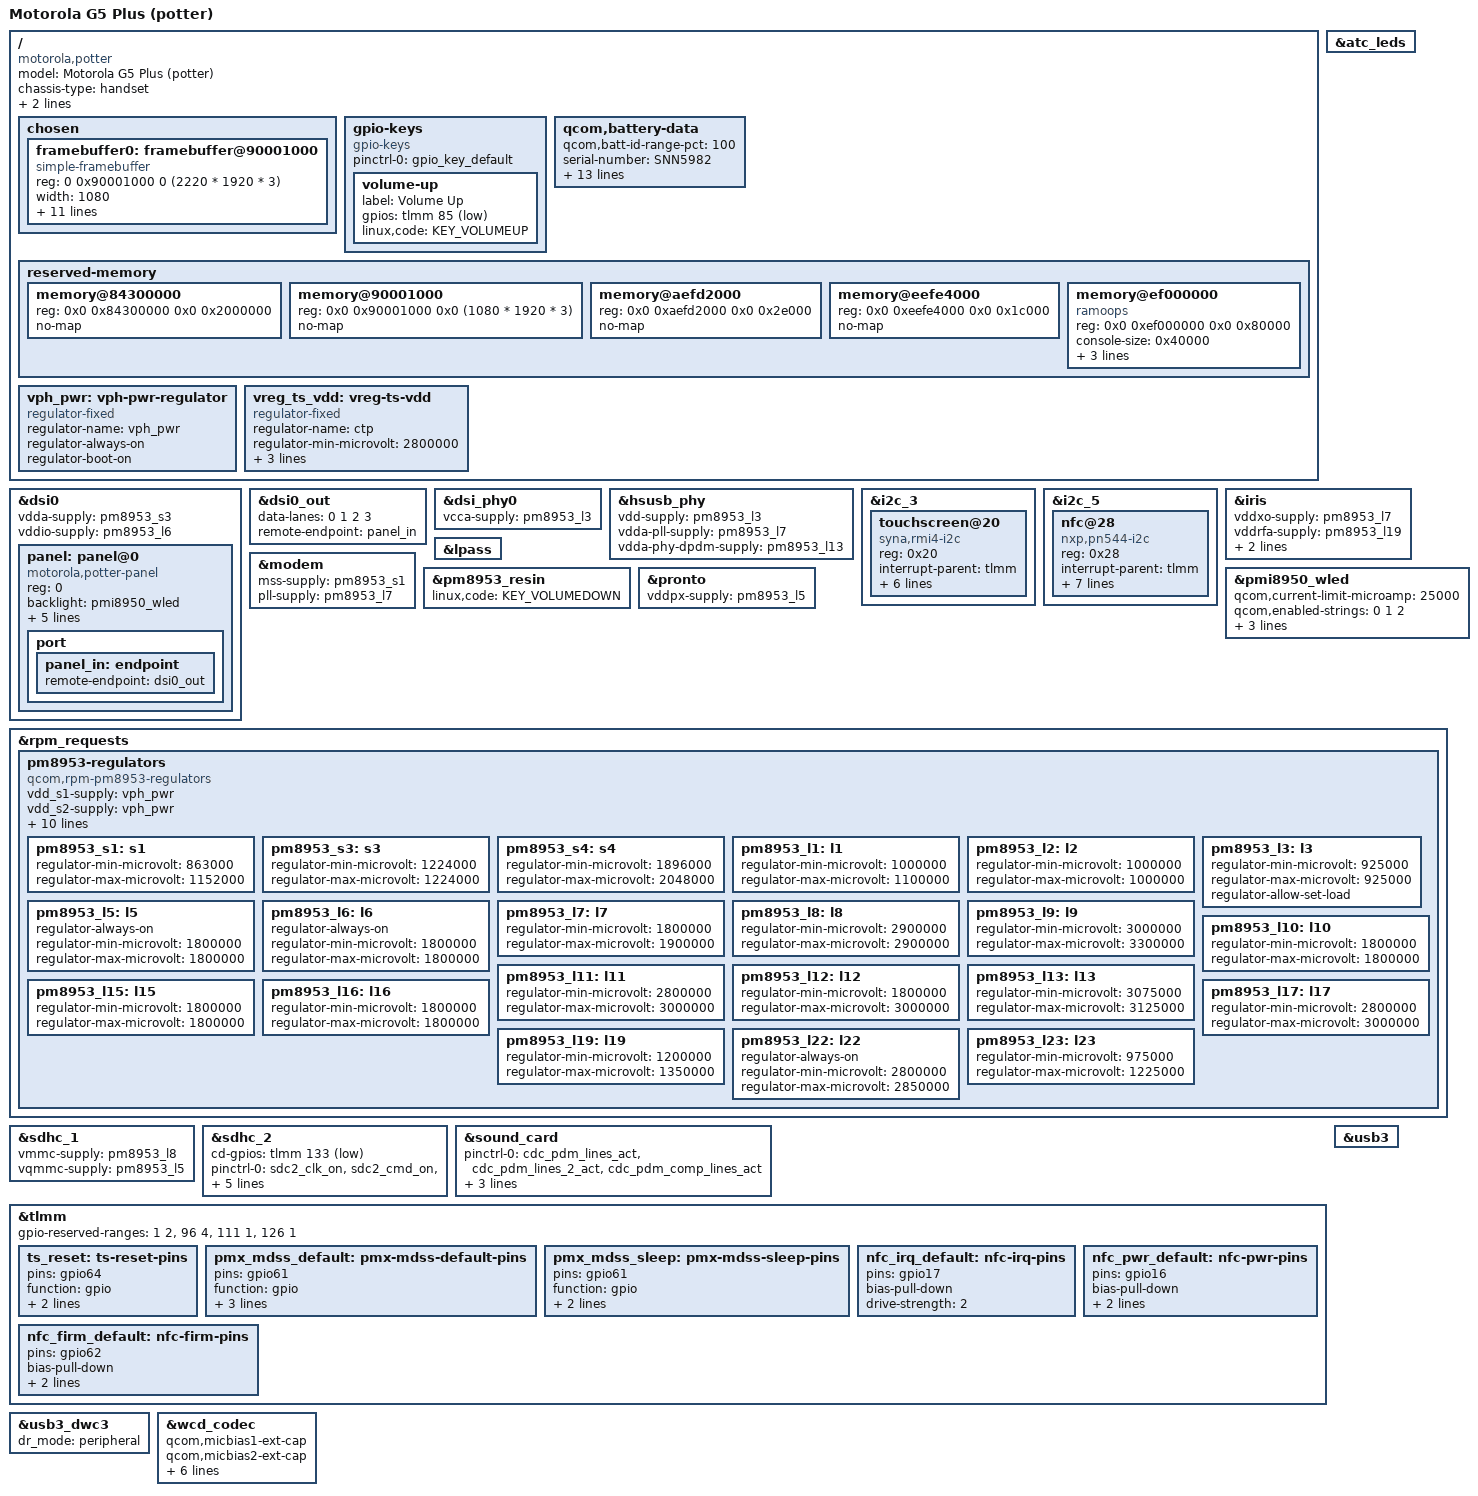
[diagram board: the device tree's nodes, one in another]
/* Copyright (c) 2022 The Linux Foundation. All rights reserved.
 *
 * This program is free software; you can redistribute it and/or modify
 * it under the terms of the GNU General Public License version 2 and
 * only version 2 as published by the Free Software Foundation.
 *
 * This program is distributed in the hope that it will be useful,
 * but WITHOUT ANY WARRANTY; without even the implied warranty of
 * MERCHANTABILITY or FITNESS FOR A PARTICULAR PURPOSE.  See the
 * GNU General Public License for more details.
 */
/dts-v1/;

#include "msm8953.dtsi"
#include "pm8953.dtsi"
#include "pmi8950.dtsi"

/ {
	model = "Motorola G5 Plus (potter)";
	compatible = "motorola,potter", "qcom,msm8953";
	chassis-type = "handset";
	qcom,msm-id = <293 0>;
	qcom,board-id = <0x46 0x83a0>;

	chosen {
		#address-cells = <2>;
		#size-cells = <2>;
		ranges;

		framebuffer0: framebuffer@90001000 {
			compatible = "simple-framebuffer";
			reg = <0 0x90001000 0 (2220 * 1920 * 3)>;

			width = <1080>;
			height = <1920>;
			stride = <(1080 * 3)>;
			format = "r8g8b8";

			power-domains = <&gcc MDSS_GDSC>;

			clocks = <&gcc GCC_MDSS_AHB_CLK>,
				 <&gcc GCC_MDSS_AXI_CLK>,
				 <&gcc GCC_MDSS_VSYNC_CLK>,
				 <&gcc GCC_MDSS_MDP_CLK>,
				 <&gcc GCC_MDSS_BYTE0_CLK>,
				 <&gcc GCC_MDSS_PCLK0_CLK>,
				 <&gcc GCC_MDSS_ESC0_CLK>;
		};
	};

	gpio-keys {
		compatible = "gpio-keys";

		pinctrl-names = "default";
		pinctrl-0 = <&gpio_key_default>;

		volume-up {
			label = "Volume Up";
			gpios = <&tlmm 85 GPIO_ACTIVE_LOW>;
			linux,code = <KEY_VOLUMEUP>;
		};
	};

	qcom,battery-data {
		qcom,batt-id-range-pct = <100>;
		serial-number = "SNN5982";
		manufacturer = "ATL";
		model = "HG40";

		qcom,max-voltage-uv = <4400000>;
		qcom,batt-id-kohm = <0>;
		qcom,battery-beta = <0>;
		qcom,battery-type = "HG40-ATL-3000mah";
		qcom,chg-rslow-comp-c1 = <3073614>;
		qcom,chg-rslow-comp-c2 = <3981400>;
		qcom,chg-rs-to-rslow = <1280731>;
		qcom,chg-rslow-comp-thr = <157>;
		qcom,thermal-coefficients = [69 86 5d 4b 62 35];
		qcom,fg-profile-data = [ E0 83 C3 7C
					 0F 81 36 77
					 65 83 4C 74
					 5C 89 67 94
					 3A 82 6D 99
					 54 BC AA C8
					 56 10 02 88
					 A7 7D A8 81
					 1F 7C 54 83
					 34 6A B6 78
					 21 86 4E 82
					 B5 99 08 BD
					 07 CA 59 0D
					 DE 0B 7F 59
					 14 70 B2 FD
					 E0 35 52 3E
					 FD 16 00 00
					 17 46 56 23
					 5F 28 00 00
					 00 00 00 00
					 00 00 00 00
					 EC 70 41 70
					 31 71 E9 83
					 EF 6E 25 5A
					 34 5A 39 7A
					 A8 6E 4D 5B
					 28 7F 6B 96
					 17 A1 62 44
					 64 A0 71 0C
					 28 00 FF 36
					 F0 11 30 03
					 00 00 00 0C ];
	};

	reserved-memory {
		/delete-node/memory@85b00000;

		memory@84300000 {
			reg = <0x0 0x84300000 0x0 0x2000000>;
			no-map;
		};

		memory@90001000 {
			reg = <0x0 0x90001000 0x0 (1080 * 1920 * 3)>;
			no-map;
		};

		memory@aefd2000 {
			reg = <0x0 0xaefd2000 0x0 0x2e000>;
			no-map;
		};

		memory@eefe4000 {
			reg = <0x0 0xeefe4000 0x0 0x1c000>;
			no-map;
		};

		memory@ef000000 {
			compatible = "ramoops";
			reg = <0x0 0xef000000 0x0 0x80000>;
			console-size = <0x40000>;
			ftrace-size = <0>;
			record-size = <0x3f800>;
			pmsg-size = <0x800>;
		};
	};

	vph_pwr: vph-pwr-regulator {
		compatible = "regulator-fixed";
		regulator-name = "vph_pwr";
		regulator-always-on;
		regulator-boot-on;
	};

	vreg_ts_vdd: vreg-ts-vdd {
		compatible = "regulator-fixed";
		regulator-name = "ctp";

		regulator-min-microvolt = <2800000>;
		regulator-max-microvolt = <2800000>;

		gpio = <&tlmm 64 GPIO_ACTIVE_HIGH>;
		enable-active-high;
	};
};

&atc_leds {
	status = "okay";
};

&dsi0 {
	status = "okay";

	vdda-supply = <&pm8953_s3>;
	vddio-supply = <&pm8953_l6>;

	panel: panel@0 {
		compatible = "motorola,potter-panel";
		reg = <0>;

		backlight = <&pmi8950_wled>;

		pinctrl-names = "default", "sleep";
		pinctrl-0 = <&pmx_mdss_default>;
		pinctrl-1 = <&pmx_mdss_sleep>;

		reset-gpios = <&tlmm 61 GPIO_ACTIVE_LOW>;

		vsp-supply = <&lab_vreg>;
		vsn-supply = <&ibb_vreg>;

		port {
			panel_in: endpoint {
				remote-endpoint = <&dsi0_out>;
			};
		};
	};
};

&dsi0_out {
	data-lanes = <0 1 2 3>;
	remote-endpoint = <&panel_in>;
};

&dsi_phy0 {
	vcca-supply = <&pm8953_l3>;
};

&hsusb_phy {
	status = "okay";

	vdd-supply = <&pm8953_l3>;
	vdda-pll-supply = <&pm8953_l7>;
	vdda-phy-dpdm-supply = <&pm8953_l13>;
};

&i2c_3 {
	status = "okay";

	touchscreen@20 {
		reg = <0x20>;
		compatible = "syna,rmi4-i2c";

		interrupt-parent = <&tlmm>;
		interrupts = <65 IRQ_TYPE_EDGE_FALLING>;

		pinctrl-names = "default";
		pinctrl-0 = <&ts_reset>;

		vdd-supply = <&pm8953_l22>;
		vio-supply = <&pm8953_l6>;

		syna,reset-delay-ms = <200>;
		syna,startup-delay-ms = <500>;
	};
};

&i2c_5 {
	status = "okay";

	nfc@28 {
		compatible = "nxp,pn544-i2c";
		reg = <0x28>;
		interrupt-parent = <&tlmm>;
		interrupts = <17 0x00>; // FIXME

		enable-gpios = <&tlmm 16 GPIO_ACTIVE_HIGH>; /* EN */
		firmware-gpios = <&tlmm 62 GPIO_ACTIVE_HIGH>; /* Firmware */

		nxp,pnxx-discharge-delay = <100>;
		nxp,pnxx-ven-inv-polarity = <0x00>;

		pinctrl-names = "default";
		pinctrl-0 = <&nfc_irq_default &nfc_pwr_default &nfc_firm_default>;
	};
};

&iris {
	vddxo-supply = <&pm8953_l7>;
	vddrfa-supply = <&pm8953_l19>;
	vddpa-supply = <&pm8953_l9>;
	vdddig-supply = <&pm8953_l5>;
};

&lpass {
	status = "okay";
};

&modem {
	status = "okay";

	mss-supply = <&pm8953_s1>;
	pll-supply = <&pm8953_l7>;
};

&pm8953_resin {
	status = "okay";
	linux,code = <KEY_VOLUMEDOWN>;
};

&pmi8950_wled {
	status = "okay";

	/* Don't copy-paste! See pmi8950.dtsi */

	qcom,current-limit-microamp = <25000>;
	qcom,enabled-strings = <0 1 2>;
	qcom,num-strings = <3>;

	qcom,cabc;
	qcom,eternal-pfet;
};

&pronto {
	status = "okay";

	vddpx-supply = <&pm8953_l5>;
};

&rpm_requests {
	pm8953-regulators {
		compatible = "qcom,rpm-pm8953-regulators";
		vdd_s1-supply = <&vph_pwr>;
		vdd_s2-supply = <&vph_pwr>;
		vdd_s3-supply = <&vph_pwr>;
		vdd_s4-supply = <&vph_pwr>;
		vdd_s5-supply = <&vph_pwr>;
		vdd_s6-supply = <&vph_pwr>;
		vdd_s7-supply = <&vph_pwr>;
		vdd_l1-supply = <&pm8953_s3>;
		vdd_l2_l3-supply = <&pm8953_s3>;
		vdd_l4_l5_l6_l7_l16_l19-supply = <&pm8953_s4>;
		vdd_l8_l11_l12_l13_l14_l15-supply = <&vph_pwr>;
		vdd_l9_l10_l17_l18_l22-supply = <&vph_pwr>;

		pm8953_s1: s1 {
			regulator-min-microvolt = <863000>;
			regulator-max-microvolt = <1152000>;
		};

		pm8953_s3: s3 {
			regulator-min-microvolt = <1224000>;
			regulator-max-microvolt = <1224000>;
		};

		pm8953_s4: s4 {
			regulator-min-microvolt = <1896000>;
			regulator-max-microvolt = <2048000>;
		};

		pm8953_l1: l1 {
			regulator-min-microvolt = <1000000>;
			regulator-max-microvolt = <1100000>;
		};

		pm8953_l2: l2 {
			regulator-min-microvolt = <1000000>;
			regulator-max-microvolt = <1000000>;
		};

		pm8953_l3: l3 {
			regulator-min-microvolt = <925000>;
			regulator-max-microvolt = <925000>;
			regulator-allow-set-load;
		};

		pm8953_l5: l5 {
			/* May fix sdcard detection */
			regulator-always-on;
			regulator-min-microvolt = <1800000>;
			regulator-max-microvolt = <1800000>;
		};

		pm8953_l6: l6 {
			regulator-always-on;
			regulator-min-microvolt = <1800000>;
			regulator-max-microvolt = <1800000>;
		};

		pm8953_l7: l7 {
			regulator-min-microvolt = <1800000>;
			regulator-max-microvolt = <1900000>;
		};

		pm8953_l8: l8 {
			regulator-min-microvolt = <2900000>;
			regulator-max-microvolt = <2900000>;
		};

		pm8953_l9: l9 {
			regulator-min-microvolt = <3000000>;
			regulator-max-microvolt = <3300000>;
		};

		pm8953_l10: l10 {
			regulator-min-microvolt = <1800000>;
			regulator-max-microvolt = <1800000>;
		};

		pm8953_l11: l11 {
			regulator-min-microvolt = <2800000>;
			regulator-max-microvolt = <3000000>;
		};

		pm8953_l12: l12 {
			regulator-min-microvolt = <1800000>;
			regulator-max-microvolt = <3000000>;
		};

		pm8953_l13: l13 {
			regulator-min-microvolt = <3075000>;
			regulator-max-microvolt = <3125000>;
		};

		pm8953_l15: l15 {
			regulator-min-microvolt = <1800000>;
			regulator-max-microvolt = <1800000>;
		};

		pm8953_l16: l16 {
			regulator-min-microvolt = <1800000>;
			regulator-max-microvolt = <1800000>;
		};

		pm8953_l17: l17 {
			regulator-min-microvolt = <2800000>;
			regulator-max-microvolt = <3000000>;
		};

		pm8953_l19: l19 {
			regulator-min-microvolt = <1200000>;
			regulator-max-microvolt = <1350000>;
		};

		pm8953_l22: l22 {
			regulator-always-on;
			regulator-min-microvolt = <2800000>;
			regulator-max-microvolt = <2850000>;
		};

		pm8953_l23: l23 {
			regulator-min-microvolt = <975000>;
			regulator-max-microvolt = <1225000>;
		};
	};
};

&sdhc_1 {
	status = "okay";

	vmmc-supply = <&pm8953_l8>;
	vqmmc-supply = <&pm8953_l5>;
};

&sdhc_2 {
	status = "okay";

	cd-gpios = <&tlmm 133 GPIO_ACTIVE_LOW>;

	pinctrl-names = "default", "sleep";
	pinctrl-0 = <&sdc2_clk_on &sdc2_cmd_on &sdc2_data_on &sdc2_cd_off>;
	pinctrl-1 = <&sdc2_clk_off &sdc2_cmd_off &sdc2_data_off &sdc2_cd_off>;

	vmmc-supply = <&pm8953_l11>;
	vqmmc-supply = <&pm8953_l12>;
};

&sound_card {
	status = "okay";

	pinctrl-names = "default", "sleep";
	pinctrl-0 = <&cdc_pdm_lines_act &cdc_pdm_lines_2_act &cdc_pdm_comp_lines_act>;
	pinctrl-1 = <&cdc_pdm_lines_sus &cdc_pdm_lines_2_sus &cdc_pdm_comp_lines_act>;

	model = "msm8916";
};

&tlmm {
	gpio-reserved-ranges = <1 2>, <96 4>, <111 1>, <126 1>;

	ts_reset: ts-reset-pins {
		pins = "gpio64";
		function = "gpio";
		drive-strength = <2>;
		bias-pull-up;
	};

	pmx_mdss_default: pmx-mdss-default-pins {
		pins = "gpio61";
		function = "gpio";
		drive-strength = <8>;
		bias-disable;
		output-high;
	};

	pmx_mdss_sleep: pmx-mdss-sleep-pins {
		pins = "gpio61";
		function = "gpio";
		drive-strength = <2>;
		bias-pull-down;
	};


	nfc_irq_default: nfc-irq-pins {
		pins = "gpio17";
		bias-pull-down;
		drive-strength = <2>;
	};

	nfc_pwr_default: nfc-pwr-pins {
		pins = "gpio16";
		bias-pull-down;
		output-low;
		drive-strength = <2>;
	};

	nfc_firm_default: nfc-firm-pins {
		pins = "gpio62";
		bias-pull-down;
		output-low;
		drive-strength = <2>;
	};
};

&usb3 {
	status = "okay";
};

&usb3_dwc3 {
	dr_mode = "peripheral";
};

&wcd_codec {
	status = "okay"; 

	qcom,micbias1-ext-cap;
	qcom,micbias2-ext-cap;
	qcom,hphl-jack-type-normally-open;
	qcom,mbhc-vthreshold-low = <75 150 237 450 500>;
	qcom,mbhc-vthreshold-high = <75 150 237 450 500>;

	vdd-cdc-io-supply = <&pm8953_l5>;
	vdd-cdc-tx-rx-cx-supply = <&pm8953_s4>;
	vdd-micbias-supply = <&pm8953_l13>;
};
